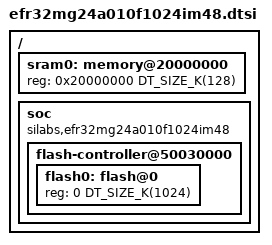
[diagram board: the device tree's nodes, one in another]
/*
 * Copyright (c) 2023 Caspar Friedrich <caspar.friedrich@ithinx.io>
 *
 * SPDX-License-Identifier: Apache-2.0
 */

#include <mem.h>
#include <silabs/efr32mg24.dtsi>

/ {
	sram0: memory@20000000 {
		reg = <0x20000000 DT_SIZE_K(128)>;
	};

	soc {
		compatible = "silabs,efr32mg24a010f1024im48",
					 "silabs,efr32mg24", "silabs,efr32",
					 "simple-bus";

		flash-controller@50030000 {
			flash0: flash@0 {
				reg = <0 DT_SIZE_K(1024)>;
			};
		};
	};
};
